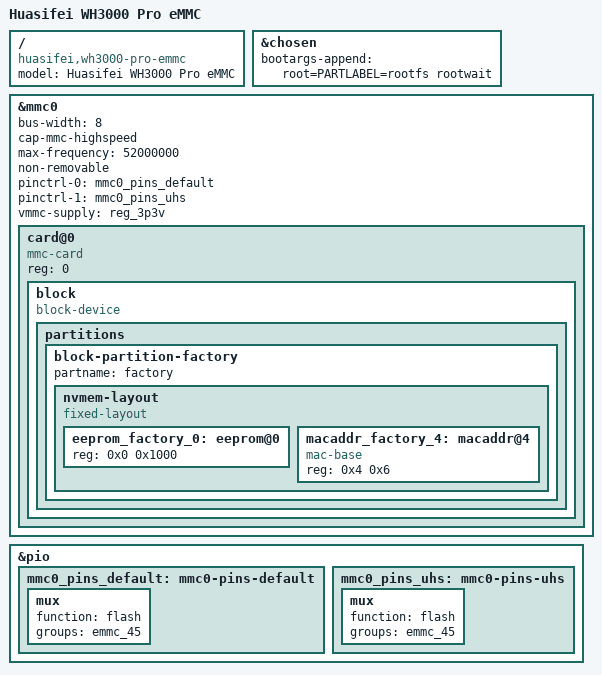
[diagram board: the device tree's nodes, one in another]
// SPDX-License-Identifier: GPL-2.0-or-later OR MIT

/dts-v1/;

#include "mt7981b-huasifei-wh3000-pro.dtsi"

/ {
	model = "Huasifei WH3000 Pro eMMC";
	compatible = "huasifei,wh3000-pro-emmc", "mediatek,mt7981";
};

&chosen {
	bootargs-append = " root=PARTLABEL=rootfs rootwait";
};

&mmc0 {
	bus-width = <8>;
	cap-mmc-highspeed;
	max-frequency = <52000000>;
	non-removable;
	#address-cells = <1>;
	#size-cells = <0>;
	pinctrl-names = "default", "state_uhs";
	pinctrl-0 = <&mmc0_pins_default>;
	pinctrl-1 = <&mmc0_pins_uhs>;
	vmmc-supply = <&reg_3p3v>;
	status = "okay";

	card@0 {
		compatible = "mmc-card";
		reg = <0>;

		block {
			compatible = "block-device";

			partitions {
				block-partition-factory {
					partname = "factory";

					nvmem-layout {
						compatible = "fixed-layout";
						#address-cells = <1>;
						#size-cells = <1>;

						eeprom_factory_0: eeprom@0 {
							reg = <0x0 0x1000>;
						};

						macaddr_factory_4: macaddr@4 {
							compatible = "mac-base";
							reg = <0x4 0x6>;
							#nvmem-cell-cells = <1>;
						};
					};
				};
			};
		};
	};
};

&pio {
	mmc0_pins_default: mmc0-pins-default {
		mux {
			function = "flash";
			groups = "emmc_45";
		};
	};

	mmc0_pins_uhs: mmc0-pins-uhs {
		mux {
			function = "flash";
			groups = "emmc_45";
		};
	};
};
